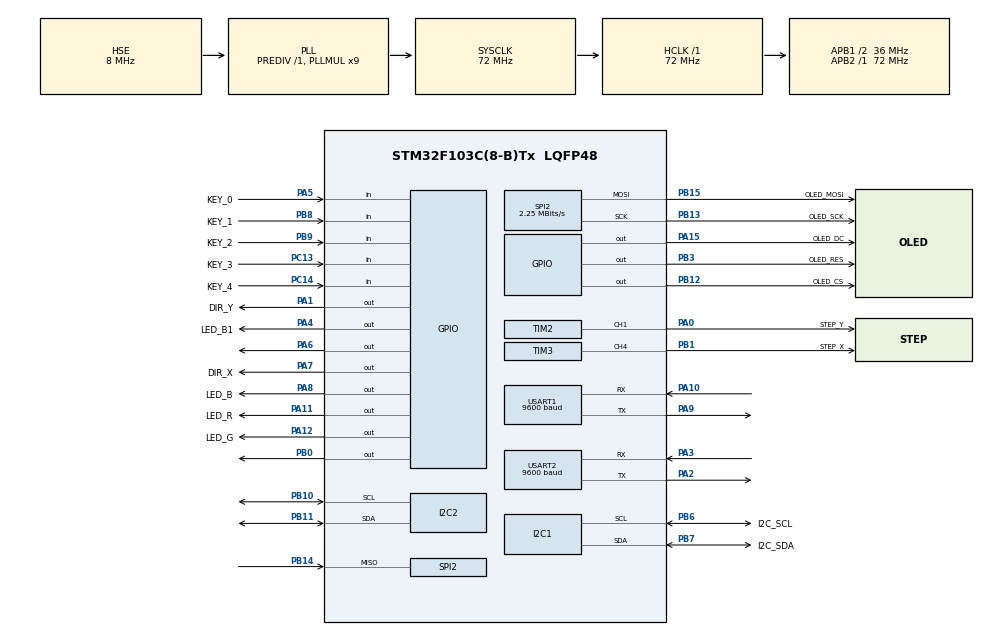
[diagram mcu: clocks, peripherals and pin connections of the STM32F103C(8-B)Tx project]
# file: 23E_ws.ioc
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Dma.Request0=TIM2_CH1
Dma.Request1=TIM3_CH4/UP
Dma.Request2=USART2_RX
Dma.TIM2_CH1.0.Direction=DMA_MEMORY_TO_PERIPH
Dma.TIM2_CH1.0.Instance=DMA1_Channel5
Dma.TIM2_CH1.0.MemDataAlignment=DMA_MDATAALIGN_HALFWORD
Dma.TIM2_CH1.0.MemInc=DMA_MINC_ENABLE
Dma.TIM2_CH1.0.Mode=DMA_NORMAL
Dma.TIM2_CH1.0.PeriphDataAlignment=DMA_PDATAALIGN_HALFWORD
Dma.TIM2_CH1.0.PeriphInc=DMA_PINC_DISABLE
Dma.TIM2_CH1.0.Priority=DMA_PRIORITY_LOW
Dma.TIM3_CH4/UP.1.Direction=DMA_MEMORY_TO_PERIPH
Dma.TIM3_CH4/UP.1.Instance=DMA1_Channel3
Dma.TIM3_CH4/UP.1.MemDataAlignment=DMA_MDATAALIGN_HALFWORD
Dma.TIM3_CH4/UP.1.MemInc=DMA_MINC_ENABLE
Dma.TIM3_CH4/UP.1.Mode=DMA_NORMAL
Dma.TIM3_CH4/UP.1.PeriphDataAlignment=DMA_PDATAALIGN_HALFWORD
Dma.TIM3_CH4/UP.1.PeriphInc=DMA_PINC_DISABLE
Dma.TIM3_CH4/UP.1.Priority=DMA_PRIORITY_LOW
Dma.USART2_RX.2.Direction=DMA_PERIPH_TO_MEMORY
Dma.USART2_RX.2.Instance=DMA1_Channel6
Dma.USART2_RX.2.MemDataAlignment=DMA_MDATAALIGN_BYTE
Dma.USART2_RX.2.MemInc=DMA_MINC_ENABLE
Dma.USART2_RX.2.Mode=DMA_NORMAL
Dma.USART2_RX.2.PeriphDataAlignment=DMA_PDATAALIGN_BYTE
Dma.USART2_RX.2.PeriphInc=DMA_PINC_DISABLE
Dma.USART2_RX.2.Priority=DMA_PRIORITY_LOW
I2C1.I2C_Mode=I2C_Standard
Mcu.Family=STM32F1
Mcu.Name=STM32F103C(8-B)Tx
Mcu.Package=LQFP48
NVIC.DMA1_Channel3_IRQn=true\:0\:0\:false\:false\:true\:false\:true\:true
NVIC.DMA1_Channel5_IRQn=true\:0\:0\:false\:false\:true\:false\:true\:true
NVIC.DMA1_Channel6_IRQn=true\:0\:0\:false\:false\:true\:false\:true\:true
NVIC.PriorityGroup=NVIC_PRIORITYGROUP_2
NVIC.TIM1_UP_IRQn=true\:0\:0\:false\:false\:true\:true\:true\:true
NVIC.TIM2_IRQn=true\:0\:0\:false\:false\:true\:true\:true\:true
NVIC.TIM3_IRQn=true\:0\:0\:false\:false\:true\:true\:true\:true
NVIC.USART2_IRQn=true\:0\:0\:false\:false\:true\:true\:true\:true
PA0-WKUP.GPIO_Label=STEP_Y
PA0-WKUP.Signal=S_TIM2_CH1_ETR
PA1.GPIO_Label=DIR_Y
PA1.GPIO_PuPd=GPIO_PULLDOWN
PA1.GPIO_Speed=GPIO_SPEED_FREQ_LOW
PA1.Signal=GPIO_Output
PA10.Mode=Asynchronous
PA10.Signal=USART1_RX
PA11.GPIO_Label=LED_R
PA11.Signal=GPIO_Output
PA12.GPIO_Label=LED_G
PA12.Signal=GPIO_Output
PA13.Mode=Serial_Wire
PA13.Signal=SYS_JTMS-SWDIO
PA14.Mode=Serial_Wire
PA14.Signal=SYS_JTCK-SWCLK
PA15.GPIO_Label=OLED_DC
PA15.Signal=GPIO_Output
PA2.Mode=Asynchronous
PA2.Signal=USART2_TX
PA3.Mode=Asynchronous
PA3.Signal=USART2_RX
PA4.GPIO_Label=LED_B1
PA4.GPIO_PuPd=GPIO_NOPULL
PA4.Signal=GPIO_Output
PA5.GPIO_Label=KEY_0
PA5.GPIO_PuPd=GPIO_PULLUP
PA5.Signal=GPIO_Input
PA6.Signal=GPIO_Output
PA7.GPIO_Label=DIR_X
PA7.GPIO_PuPd=GPIO_PULLDOWN
PA7.GPIO_Speed=GPIO_SPEED_FREQ_LOW
PA7.Signal=GPIO_Output
PA8.GPIO_Label=LED_B
PA8.GPIO_PuPd=GPIO_NOPULL
PA8.GPIO_Speed=GPIO_SPEED_FREQ_LOW
PA8.Signal=GPIO_Output
PA9.Mode=Asynchronous
PA9.Signal=USART1_TX
PB0.Signal=GPIO_Output
PB1.GPIO_Label=STEP_X
PB1.Signal=S_TIM3_CH4
PB10.Mode=I2C
PB10.Signal=I2C2_SCL
PB11.Mode=I2C
PB11.Signal=I2C2_SDA
PB12.GPIO_Label=OLED_CS
PB12.GPIO_Speed=GPIO_SPEED_FREQ_HIGH
PB12.Signal=GPIO_Output
PB13.GPIO_Label=OLED_SCK
PB13.Mode=Full_Duplex_Master
PB13.Signal=SPI2_SCK
PB14.Mode=Full_Duplex_Master
PB14.Signal=SPI2_MISO
PB15.GPIO_Label=OLED_MOSI
PB15.Mode=Full_Duplex_Master
PB15.Signal=SPI2_MOSI
PB3.GPIO_Label=OLED_RES
PB3.Signal=GPIO_Output
PB6.GPIO_Label=I2C_SCL
PB6.GPIO_Speed=GPIO_SPEED_FREQ_HIGH
PB6.Mode=I2C
PB6.Signal=I2C1_SCL
PB7.GPIO_Label=I2C_SDA
PB7.GPIO_Mode=GPIO_MODE_AF_OD
PB7.GPIO_Speed=GPIO_SPEED_FREQ_HIGH
PB7.Mode=I2C
PB7.Signal=I2C1_SDA
PB8.GPIO_Label=KEY_1
PB8.GPIO_PuPd=GPIO_PULLUP
PB8.Signal=GPIO_Input
PB9.GPIO_Label=KEY_2
PB9.GPIO_PuPd=GPIO_PULLUP
PB9.Signal=GPIO_Input
PC13-TAMPER-RTC.GPIO_Label=KEY_3
PC13-TAMPER-RTC.GPIO_PuPd=GPIO_PULLUP
PC13-TAMPER-RTC.Signal=GPIO_Input
PC14-OSC32_IN.GPIO_Label=KEY_4
PC14-OSC32_IN.GPIO_PuPd=GPIO_PULLUP
PC14-OSC32_IN.Signal=GPIO_Input
PD0-OSC_IN.Mode=HSE-External-Oscillator
PD0-OSC_IN.Signal=RCC_OSC_IN
PD1-OSC_OUT.Mode=HSE-External-Oscillator
PD1-OSC_OUT.Signal=RCC_OSC_OUT
ProjectManager.HeapSize=0x200
ProjectManager.StackSize=0x400
ProjectManager.TargetToolchain=MDK-ARM V5.32
RCC.AHBFreq_Value=72000000
RCC.APB1CLKDivider=RCC_HCLK_DIV2
RCC.APB1Freq_Value=36000000
RCC.APB1TimFreq_Value=72000000
RCC.APB2Freq_Value=72000000
RCC.APB2TimFreq_Value=72000000
RCC.HCLKFreq_Value=72000000
RCC.PLLMUL=RCC_PLL_MUL9
RCC.PLLSourceVirtual=RCC_PLLSOURCE_HSE
RCC.SYSCLKFreq_VALUE=72000000
RCC.SYSCLKSource=RCC_SYSCLKSOURCE_PLLCLK
RCC.USBFreq_Value=72000000
SH.S_TIM2_CH1_ETR.0=TIM2_CH1,PWM Generation1 CH1
SH.S_TIM3_CH4.0=TIM3_CH4,PWM Generation4 CH4
SPI2.BaudRatePrescaler=SPI_BAUDRATEPRESCALER_16
SPI2.CLKPhase=SPI_PHASE_1EDGE
SPI2.CalculateBaudRate=2.25 MBits/s
SPI2.Direction=SPI_DIRECTION_2LINES
SPI2.Mode=SPI_MODE_MASTER
SPI2.VirtualType=VM_MASTER
TIM1.AutoReloadPreload=TIM_AUTORELOAD_PRELOAD_ENABLE
TIM1.Period=999
TIM1.Prescaler=72-1
TIM2.AutoReloadPreload=TIM_AUTORELOAD_PRELOAD_DISABLE
TIM2.Channel-PWM\ Generation1\ CH1=TIM_CHANNEL_1
TIM2.Period=999
TIM2.Prescaler=71
TIM2.Pulse-PWM\ Generation1\ CH1=0
TIM3.Channel-PWM\ Generation4\ CH4=TIM_CHANNEL_4
TIM3.Period=999
TIM3.Prescaler=71
USART1.BaudRate=9600
USART1.VirtualMode=VM_ASYNC
USART2.BaudRate=9600
USART2.VirtualMode=VM_ASYNC
VP_TIM1_VS_ClockSourceINT.Mode=Internal
board=custom

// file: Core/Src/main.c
/* USER CODE BEGIN Header */
/**
  ******************************************************************************
  * @file           : main.c
  * @brief          : Main program body
  ******************************************************************************
  * @attention
  *
  * Copyright (c) 2024 STMicroelectronics.
  * All rights reserved.
  *
  * This software is licensed under terms that can be found in the LICENSE file
  * in the root directory of this software component.
  * If no LICENSE file comes with this software, it is provided AS-IS.
  *
  ******************************************************************************
  */
/* USER CODE END Header */
#include "main.h"
#include "dma.h"
#include "i2c.h"
#include "spi.h"
#include "tim.h"
#include "usart.h"
#include "gpio.h"

/* USER CODE BEGIN Includes */
#include "common_inc.h"
/* USER CODE END Includes */

void SystemClock_Config(void);

int main(void)
{

  /* MCU Configuration--------------------------------------------------------*/

  /* Reset of all peripherals, Initializes the Flash interface and the Systick. */
  HAL_Init();

  /* Configure the system clock */
  SystemClock_Config();

  /* Initialize all configured peripherals */
  MX_GPIO_Init();
  MX_DMA_Init();
  MX_TIM1_Init();
  MX_I2C1_Init();
  MX_USART2_UART_Init();
  MX_SPI2_Init();
  MX_TIM2_Init();
  MX_I2C2_Init();
  MX_USART1_UART_Init();
  MX_TIM3_Init();
  /* USER CODE BEGIN 2 */
  mainloop();
  /* USER CODE END 2 */

  /* Infinite loop */
  while (1)
  {

  }
}

void SystemClock_Config(void)
{
  RCC_OscInitTypeDef RCC_OscInitStruct = {0};
  RCC_ClkInitTypeDef RCC_ClkInitStruct = {0};

  /** Initializes the RCC Oscillators according to the specified parameters
  * in the RCC_OscInitTypeDef structure.
  */
  RCC_OscInitStruct.OscillatorType = RCC_OSCILLATORTYPE_HSE;
  RCC_OscInitStruct.HSEState = RCC_HSE_ON;
  RCC_OscInitStruct.HSEPredivValue = RCC_HSE_PREDIV_DIV1;
  RCC_OscInitStruct.HSIState = RCC_HSI_ON;
  RCC_OscInitStruct.PLL.PLLState = RCC_PLL_ON;
  RCC_OscInitStruct.PLL.PLLSource = RCC_PLLSOURCE_HSE;
  RCC_OscInitStruct.PLL.PLLMUL = RCC_PLL_MUL9;
  if (HAL_RCC_OscConfig(&RCC_OscInitStruct) != HAL_OK)
  {
    Error_Handler();
  }

  /** Initializes the CPU, AHB and APB buses clocks
  */
  RCC_ClkInitStruct.ClockType = RCC_CLOCKTYPE_HCLK|RCC_CLOCKTYPE_SYSCLK
                              |RCC_CLOCKTYPE_PCLK1|RCC_CLOCKTYPE_PCLK2;
  RCC_ClkInitStruct.SYSCLKSource = RCC_SYSCLKSOURCE_PLLCLK;
  RCC_ClkInitStruct.AHBCLKDivider = RCC_SYSCLK_DIV1;
  RCC_ClkInitStruct.APB1CLKDivider = RCC_HCLK_DIV2;
  RCC_ClkInitStruct.APB2CLKDivider = RCC_HCLK_DIV1;

  if (HAL_RCC_ClockConfig(&RCC_ClkInitStruct, FLASH_LATENCY_2) != HAL_OK)
  {
    Error_Handler();
  }
}

void Error_Handler(void)
{
  __disable_irq();
  while (1)
  {
  }
}
